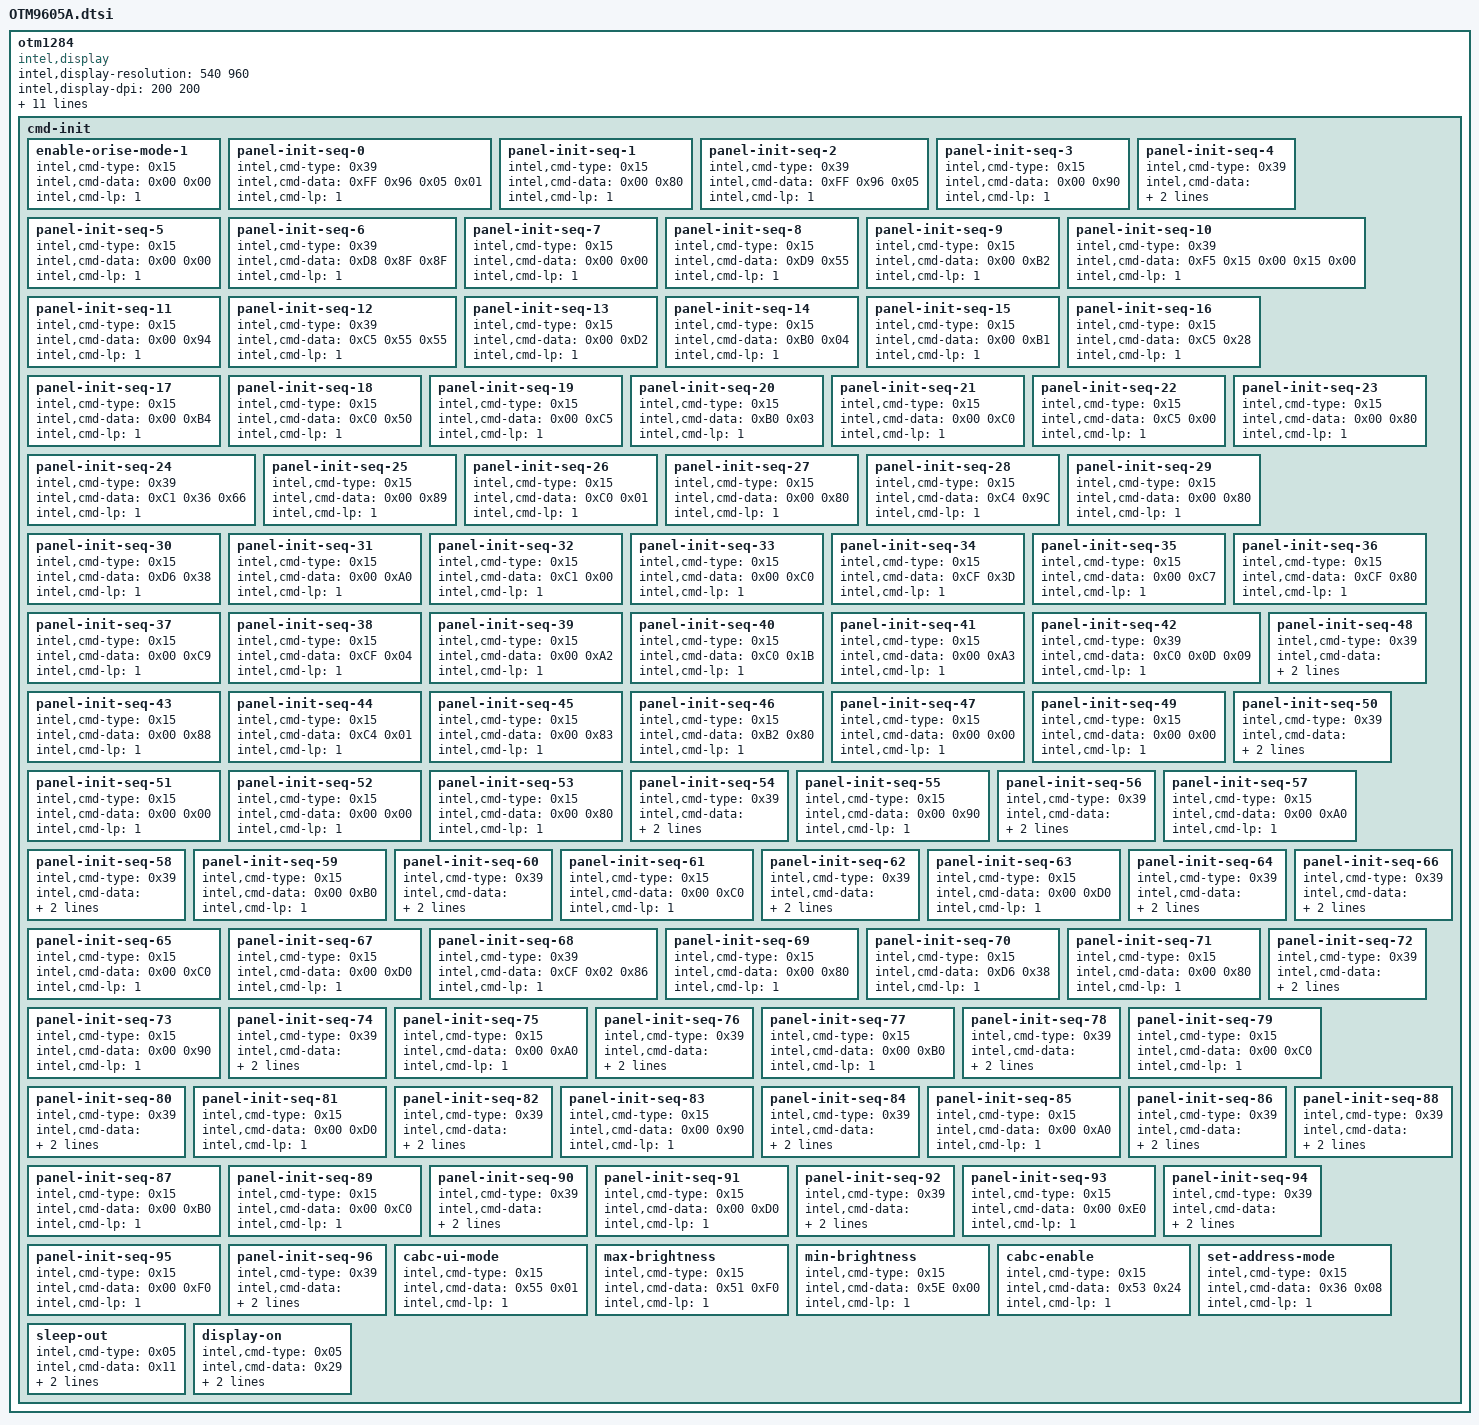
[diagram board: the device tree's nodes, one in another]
	otm1284 {
		compatible = "intel,display";
		intel,display-resolution= <540 960>;
		intel,display-dpi= <200 200>;

		/* MIPI-DSI video mode settings */
		intel,display-vid-hfp-hs-bytes = <93>;
		intel,display-vid-hbp-hs-bytes = <93>;
		intel,display-vid-hsa-hs-bytes = <24>;
		intel,display-vid-vfp-lines = <15>;
		intel,display-vid-vbp-lines = <16>;
		intel,display-vid-vsa-lines = <2>;

		intel,display-vid-mode = "pulses";
		intel,display-vid-id = <0>;
		intel,display-vid-pixel = "24packed";
		intel,display-vid-fill_buf_to = <0x1F>;

		intel,display-reset = <1 1 0 2 1 10>;

		cmd-init {
			enable-orise-mode-1 {
				intel,cmd-type = <0x15>;
				intel,cmd-data = <0x00 0x00>;
				intel,cmd-lp = <1>;
			};
			panel-init-seq-0 {
				intel,cmd-type = <0x39>;
				intel,cmd-data = <0xFF 0x96 0x05 0x01>;
				intel,cmd-lp = <1>;
			};
			panel-init-seq-1 {
				intel,cmd-type = <0x15>;
				intel,cmd-data = <0x00 0x80>;
				intel,cmd-lp = <1>;
			};
			panel-init-seq-2 {
				intel,cmd-type = <0x39>;
				intel,cmd-data = <0xFF 0x96 0x05>;
				intel,cmd-lp = <1>;
			};
			panel-init-seq-3 {
				intel,cmd-type = <0x15>;
				intel,cmd-data = <0x00 0x90>;
				intel,cmd-lp = <1>;
			};
			panel-init-seq-4 {
				intel,cmd-type = <0x39>;
				intel,cmd-data = <0xC5 0x96 0x7B 0x06 0x33 0x55 0x55 0x31>;
				intel,cmd-lp = <1>;
			};
			panel-init-seq-5 {
				intel,cmd-type = <0x15>;
				intel,cmd-data = <0x00 0x00>;
				intel,cmd-lp = <1>;
			};
			panel-init-seq-6 {
				intel,cmd-type = <0x39>;
				intel,cmd-data = <0xD8 0x8F 0x8F>;  //0x8F = 4.9
				intel,cmd-lp = <1>;
			};
	
			panel-init-seq-7 {
				intel,cmd-type = <0x15>;
				intel,cmd-data = <0x00 0x00>;
				intel,cmd-lp = <1>;
			};
			panel-init-seq-8 {
				intel,cmd-type = <0x15>;
				intel,cmd-data = <0xD9 0x55>; //By Panel
				intel,cmd-lp = <1>;
			};
			panel-init-seq-9 {
				intel,cmd-type = <0x15>;
				intel,cmd-data = <0x00 0xB2>;
				intel,cmd-lp = <1>;
			};
			panel-init-seq-10 {
				intel,cmd-type = <0x39>;
				intel,cmd-data = <0xF5 0x15 0x00 0x15 0x00>;
				intel,cmd-lp = <1>;
			};
			panel-init-seq-11 {
				intel,cmd-type = <0x15>;
				intel,cmd-data = <0x00 0x94>;
				intel,cmd-lp = <1>;
			};
			panel-init-seq-12 {
				intel,cmd-type = <0x39>;
				intel,cmd-data = <0xC5 0x55 0x55>;
				intel,cmd-lp = <1>;
			};
			panel-init-seq-13 {
				intel,cmd-type = <0x15>;
				intel,cmd-data = <0x00 0xD2>;
				intel,cmd-lp = <1>;
			};
			panel-init-seq-14 {
				intel,cmd-type = <0x15>;
				intel,cmd-data = <0xB0 0x04>;
				intel,cmd-lp = <1>;
			};
			panel-init-seq-15 {
				intel,cmd-type = <0x15>;
				intel,cmd-data = <0x00 0xB1>;
				intel,cmd-lp = <1>;
			};
			panel-init-seq-16 {
				intel,cmd-type = <0x15>;
				intel,cmd-data = <0xC5 0x28>;
				intel,cmd-lp = <1>;
			};
			panel-init-seq-17 {
				intel,cmd-type = <0x15>;
				intel,cmd-data = <0x00 0xB4>;
				intel,cmd-lp = <1>;
			};
			panel-init-seq-18 {
				intel,cmd-type = <0x15>;
				intel,cmd-data = <0xC0 0x50>;
				intel,cmd-lp = <1>;
			};
			panel-init-seq-19 {
				intel,cmd-type = <0x15>;
				intel,cmd-data = <0x00 0xC5>;
				intel,cmd-lp = <1>;
			};
			panel-init-seq-20 {
				intel,cmd-type = <0x15>;
				intel,cmd-data = <0xB0 0x03>;
				intel,cmd-lp = <1>;
			};
			panel-init-seq-21 {
				intel,cmd-type = <0x15>;
				intel,cmd-data = <0x00 0xC0>;
				intel,cmd-lp = <1>;
			};
			panel-init-seq-22 {
				intel,cmd-type = <0x15>;
				intel,cmd-data = <0xC5 0x00>;
				intel,cmd-lp = <1>;
			};
			panel-init-seq-23 {
				intel,cmd-type = <0x15>;
				intel,cmd-data = <0x00 0x80>;
				intel,cmd-lp = <1>;
			};
			panel-init-seq-24 {
				intel,cmd-type = <0x39>;
				intel,cmd-data = <0xC1 0x36 0x66>;
				intel,cmd-lp = <1>;
			};
			panel-init-seq-25 {
				intel,cmd-type = <0x15>;
				intel,cmd-data = <0x00 0x89>;
				intel,cmd-lp = <1>;
			};
			panel-init-seq-26 {
				intel,cmd-type = <0x15>;
				intel,cmd-data = <0xC0 0x01>;
				intel,cmd-lp = <1>;
			};
			panel-init-seq-27 {
				intel,cmd-type = <0x15>;
				intel,cmd-data = <0x00 0x80>;
				intel,cmd-lp = <1>;
			};
			panel-init-seq-28 {
				intel,cmd-type = <0x15>;
				intel,cmd-data = <0xC4 0x9C>;
				intel,cmd-lp = <1>;
			};
			panel-init-seq-29 {
				intel,cmd-type = <0x15>;
				intel,cmd-data = <0x00 0x80>;
				intel,cmd-lp = <1>;
			};
			panel-init-seq-30 {
				intel,cmd-type = <0x15>;
				intel,cmd-data = <0xD6 0x38>;
				intel,cmd-lp = <1>;
			};
			panel-init-seq-31 {
				intel,cmd-type = <0x15>;
				intel,cmd-data = <0x00 0xA0>;
				intel,cmd-lp = <1>;
			};
			panel-init-seq-32 {
				intel,cmd-type = <0x15>;
				intel,cmd-data = <0xC1 0x00>;
				intel,cmd-lp = <1>;
			};
			panel-init-seq-33 {
				intel,cmd-type = <0x15>;
				intel,cmd-data = <0x00 0xC0>;
				intel,cmd-lp = <1>;
			};
			panel-init-seq-34 {
				intel,cmd-type = <0x15>;
				intel,cmd-data = <0xCF 0x3D>;
				intel,cmd-lp = <1>;
			};
			panel-init-seq-35 {
				intel,cmd-type = <0x15>;
				intel,cmd-data = <0x00 0xC7>;
				intel,cmd-lp = <1>;
			};
			panel-init-seq-36 {
				intel,cmd-type = <0x15>;
				intel,cmd-data = <0xCF 0x80>;
				intel,cmd-lp = <1>;
			};
			panel-init-seq-37 {
				intel,cmd-type = <0x15>;
				intel,cmd-data = <0x00 0xC9>;
				intel,cmd-lp = <1>;
			};
			panel-init-seq-38 {
				intel,cmd-type = <0x15>;
				intel,cmd-data = <0xCF 0x04>;
				intel,cmd-lp = <1>;
			};
			panel-init-seq-39 {
				intel,cmd-type = <0x15>;
				intel,cmd-data = <0x00 0xA2>; //0xC0A2 PL
				intel,cmd-lp = <1>;
			};
			panel-init-seq-40 {
				intel,cmd-type = <0x15>;
				intel,cmd-data = <0xC0 0x1B>;
				intel,cmd-lp = <1>;
			};
			panel-init-seq-41 {
				intel,cmd-type = <0x15>;
				intel,cmd-data = <0x00 0xA3>; //0xC0A2-A3 PCH1+PCH2
				intel,cmd-lp = <1>;
			};
			panel-init-seq-42 {
				intel,cmd-type = <0x39>;
				intel,cmd-data = <0xC0 0x0D 0x09>;
				intel,cmd-lp = <1>;
			};
			panel-init-seq-43 {
				intel,cmd-type = <0x15>;
				intel,cmd-data = <0x00 0x88>; //0xC488 CR
				intel,cmd-lp = <1>;
			};
			panel-init-seq-44 {
				intel,cmd-type = <0x15>;
				intel,cmd-data = <0xC4 0x01>;
				intel,cmd-lp = <1>;
			};
			panel-init-seq-45 {
				intel,cmd-type = <0x15>;
				intel,cmd-data = <0x00 0x83>;
				intel,cmd-lp = <1>;
			};
			panel-init-seq-46 {
				intel,cmd-type = <0x15>;
				intel,cmd-data = <0xB2 0x80>;
				intel,cmd-lp = <1>;
			};
			panel-init-seq-47 {
				intel,cmd-type = <0x15>;
				intel,cmd-data = <0x00 0x00>;
				intel,cmd-lp = <1>;
			};
			panel-init-seq-48 {
				intel,cmd-type = <0x39>;
				intel,cmd-data = <0xE1 0x03 0x07 0x0D 0x0D 0x06 0x0E 0x0D 0x08 0x04 0x08 0x0B 0x08 0x0E 0x16 0x11 0x0A>;
				intel,cmd-lp = <1>;
			};
			panel-init-seq-49 {
				intel,cmd-type = <0x15>;
				intel,cmd-data = <0x00 0x00>;
				intel,cmd-lp = <1>;
			};
			panel-init-seq-50 {
				intel,cmd-type = <0x39>;
				intel,cmd-data = <0xE2 0x03 0x07 0x0D 0x0D 0x06 0x0E 0x0D 0x08 0x04 0x08 0x0B 0x08 0x0E 0x16 0x11 0x0A>;
				intel,cmd-lp = <1>;
			};
			panel-init-seq-51 {
				intel,cmd-type = <0x15>;
				intel,cmd-data = <0x00 0x00>;
				intel,cmd-lp = <1>;
			};
			panel-init-seq-52 {
				intel,cmd-type = <0x15>;
				intel,cmd-data = <0x00 0x00>;
				intel,cmd-lp = <1>;
			};
			panel-init-seq-53 {
				intel,cmd-type = <0x15>;
				intel,cmd-data = <0x00 0x80>;
				intel,cmd-lp = <1>;
			};
			panel-init-seq-54 {
				intel,cmd-type = <0x39>;
				intel,cmd-data = <0xCE 0x8B 0x03 0x00 0x8A 0x03 0x00 0x00 0x00 0x00 0x00 0x00 0x00>;
				intel,cmd-lp = <1>;
			};
			panel-init-seq-55 {
				intel,cmd-type = <0x15>;
				intel,cmd-data = <0x00 0x90>;
				intel,cmd-lp = <1>;
			};
			panel-init-seq-56 {
				intel,cmd-type = <0x39>;
				intel,cmd-data = <0xCE 0x00 0x00 0x00 0x00 0x00 0x00 0x00 0x00 0x00 0x00 0x00 0x00 0x00 0x00>;
				intel,cmd-lp = <1>;
			};
			panel-init-seq-57 {
				intel,cmd-type = <0x15>;
				intel,cmd-data = <0x00 0xA0>;
				intel,cmd-lp = <1>;
			};
			panel-init-seq-58 {
				intel,cmd-type = <0x39>;
				intel,cmd-data = <0xCE 0x38 0x09 0x03 0xC2 0x00 0x17 0x00 0x38 0x08 0x03 0xC3 0x00 0x17 0x00>;
				intel,cmd-lp = <1>;
			};
			panel-init-seq-59 {
				intel,cmd-type = <0x15>;
				intel,cmd-data = <0x00 0xB0>;
				intel,cmd-lp = <1>;
			};
			panel-init-seq-60 {
				intel,cmd-type = <0x39>;
				intel,cmd-data = <0xCE 0x38 0x07 0x03 0xC4 0x00 0x17 0x00 0x38 0x06 0x03 0xCA 0x00 0x17 0x00>;
				intel,cmd-lp = <1>;
			};
			panel-init-seq-61 {
				intel,cmd-type = <0x15>;
				intel,cmd-data = <0x00 0xC0>;
				intel,cmd-lp = <1>;
			};
			panel-init-seq-62 {
				intel,cmd-type = <0x39>;
				intel,cmd-data = <0xCE 0x38 0x05 0x03 0xC6 0x00 0x17 0x00 0x38 0x04 0x03 0xC7 0x00 0x17 0x00>;
				intel,cmd-lp = <1>;
			};
			panel-init-seq-63 {
				intel,cmd-type = <0x15>;
				intel,cmd-data = <0x00 0xD0>;
				intel,cmd-lp = <1>;
			};
			panel-init-seq-64 {
				intel,cmd-type = <0x39>;
				intel,cmd-data = <0xCE 0x38 0x03 0x03 0xC8 0x00 0x17 0x00 0x38 0x02 0x03 0xC9 0x00 0x17 0x00>;
				intel,cmd-lp = <1>;
			};
			panel-init-seq-65 {
				intel,cmd-type = <0x15>;
				intel,cmd-data = <0x00 0xC0>;
				intel,cmd-lp = <1>;
			};
			panel-init-seq-66 {
				intel,cmd-type = <0x39>;
				intel,cmd-data = <0xCF 0x09 0x02 0x20 0x20 0x00 0x00 0x01 0x80 0x20 0x04>;
				intel,cmd-lp = <1>;
			};
			panel-init-seq-67 {
				intel,cmd-type = <0x15>;
				intel,cmd-data = <0x00 0xD0>;
				intel,cmd-lp = <1>;
			};
			panel-init-seq-68 {
				intel,cmd-type = <0x39>;
				intel,cmd-data = <0xCF 0x02 0x86>;
				intel,cmd-lp = <1>;
			};
			panel-init-seq-69 {
				intel,cmd-type = <0x15>;
				intel,cmd-data = <0x00 0x80>;
				intel,cmd-lp = <1>;
			};
			panel-init-seq-70 {
				intel,cmd-type = <0x15>;
				intel,cmd-data = <0xD6 0x38>;
				intel,cmd-lp = <1>;
			};
			panel-init-seq-71 {
				intel,cmd-type = <0x15>;
				intel,cmd-data = <0x00 0x80>;
				intel,cmd-lp = <1>;
			};
			panel-init-seq-72 {
				intel,cmd-type = <0x39>;
				intel,cmd-data = <0xCC 0x00 0x00 0x00 0x02 0x00 0x0A 0x0C 0x0E 0x10 0x00>;
				intel,cmd-lp = <1>;
			};
			panel-init-seq-73 {
				intel,cmd-type = <0x15>;
				intel,cmd-data = <0x00 0x90>;
				intel,cmd-lp = <1>;
			};
			panel-init-seq-74 {
				intel,cmd-type = <0x39>;
				intel,cmd-data = <0xCC 0x21 0x00 0x22 0x00 0x00 0x00 0x00 0x00 0x00 0x00 0x00 0x00 0x00 0x01 0x00>;
				intel,cmd-lp = <1>;
			};
			panel-init-seq-75 {
				intel,cmd-type = <0x15>;
				intel,cmd-data = <0x00 0xA0>;
				intel,cmd-lp = <1>;
			};
			panel-init-seq-76 {
				intel,cmd-type = <0x39>;
				intel,cmd-data = <0xCC 0x09 0x0B 0x0D 0x0F 0x00 0x21 0x00 0x22 0x00 0x00 0x00 0x00 0x00 0x00 0x00>;
				intel,cmd-lp = <1>;
			};
			panel-init-seq-77 {
				intel,cmd-type = <0x15>;
				intel,cmd-data = <0x00 0xB0>;
				intel,cmd-lp = <1>;
			};
			panel-init-seq-78 {
				intel,cmd-type = <0x39>;
				intel,cmd-data = <0xCC 0x00 0x00 0x00 0x00 0x00 0x00 0x00 0x00 0x00 0x00>;
				intel,cmd-lp = <1>;
			};
			panel-init-seq-79 {
				intel,cmd-type = <0x15>;
				intel,cmd-data = <0x00 0xC0>;
				intel,cmd-lp = <1>;
			};
			panel-init-seq-80 {
				intel,cmd-type = <0x39>;
				intel,cmd-data = <0xCC 0x00 0x00 0x00 0x00 0x00 0x00 0x00 0x00 0x00 0x00 0x00 0x00 0x00 0x00 0x00>;
				intel,cmd-lp = <1>;
			};
			panel-init-seq-81 {
				intel,cmd-type = <0x15>;
				intel,cmd-data = <0x00 0xD0>;
				intel,cmd-lp = <1>;
			};
			panel-init-seq-82 {
				intel,cmd-type = <0x39>;
				intel,cmd-data = <0xCC 0x00 0x00 0x00 0x00 0x00 0x00 0x00 0x00 0x00 0x00 0x00 0x00 0x00 0x00 0x00>;
				intel,cmd-lp = <1>;
			};
			panel-init-seq-83 {
				intel,cmd-type = <0x15>;
				intel,cmd-data = <0x00 0x90>;
				intel,cmd-lp = <1>;
			};
			panel-init-seq-84 {
				intel,cmd-type = <0x39>;
				intel,cmd-data = <0xCB 0x00 0x00 0x00 0x04 0x04 0x04 0x04 0x04 0x04 0x00 0x04 0x00 0x04 0x00 0x00>;
				intel,cmd-lp = <1>;
			};
			panel-init-seq-85 {
				intel,cmd-type = <0x15>;
				intel,cmd-data = <0x00 0xA0>;
				intel,cmd-lp = <1>;
			};
			panel-init-seq-86 {
				intel,cmd-type = <0x39>;
				intel,cmd-data = <0xCB 0x00 0x00 0x00 0x00 0x00 0x00 0x00 0x00 0x04 0x04 0x04 0x04 0x04 0x04 0x00>;
				intel,cmd-lp = <1>;
			};
			panel-init-seq-87 {
				intel,cmd-type = <0x15>;
				intel,cmd-data = <0x00 0xB0>;
				intel,cmd-lp = <1>;
			};
			panel-init-seq-88 {
				intel,cmd-type = <0x39>;
				intel,cmd-data = <0xCB 0x04 0x00 0x04 0x00 0x00 0x00 0x00 0x00 0x00 0x00>;
				intel,cmd-lp = <1>;
			};
			panel-init-seq-89 {
				intel,cmd-type = <0x15>;
				intel,cmd-data = <0x00 0xC0>;
				intel,cmd-lp = <1>;
			};
			panel-init-seq-90 {
				intel,cmd-type = <0x39>;
				intel,cmd-data = <0xCB 0x00 0x00 0x00 0x04 0x04 0x04 0x04 0x04 0x04 0x00 0x04 0x00 0x04 0x00 0x00>;
				intel,cmd-lp = <1>;
			};
			panel-init-seq-91 {
				intel,cmd-type = <0x15>;
				intel,cmd-data = <0x00 0xD0>;
				intel,cmd-lp = <1>;
			};
			panel-init-seq-92 {
				intel,cmd-type = <0x39>;
				intel,cmd-data = <0xCB 0x00 0x00 0x00 0x00 0x00 0x00 0x00 0x00 0x04 0x04 0x04 0x04 0x04 0x04 0x00>;
				intel,cmd-lp = <1>;
			};
			panel-init-seq-93 {
				intel,cmd-type = <0x15>;
				intel,cmd-data = <0x00 0xE0>;
				intel,cmd-lp = <1>;
			};
			panel-init-seq-94 {
				intel,cmd-type = <0x39>;
				intel,cmd-data = <0xCB 0x04 0x00 0x04 0x00 0x00 0x00 0x00 0x00 0x00 0x00>;
				intel,cmd-lp = <1>;
			};
			panel-init-seq-95 {
				intel,cmd-type = <0x15>;
				intel,cmd-data = <0x00 0xF0>;
				intel,cmd-lp = <1>;
			};
			panel-init-seq-96 {
				intel,cmd-type = <0x39>;
				intel,cmd-data = <0xCB 0xFF 0xFF 0xFF 0xFF 0xFF 0xFF 0xFF 0xFF 0xFF 0xFF>;
				intel,cmd-lp = <1>;
			};

			cabc-ui-mode{
				intel,cmd-type = <0x15>;
				intel,cmd-data = <0x55 0x01>;
				intel,cmd-lp = <1>;
			};
			max-brightness{
				intel,cmd-type = <0x15>;
				intel,cmd-data = <0x51 0xF0>;
				intel,cmd-lp = <1>;
			};
			min-brightness{
				intel,cmd-type = <0x15>;
				intel,cmd-data = <0x5E 0x00>;
				intel,cmd-lp = <1>;
			};
			cabc-enable{
				intel,cmd-type = <0x15>;
				intel,cmd-data = <0x53 0x24>;
				intel,cmd-lp = <1>;
			};
			set-address-mode {
				intel,cmd-type = <0x15>;
				intel,cmd-data = <0x36 0x08>;
				intel,cmd-lp = <1>;
			};
			sleep-out{
				intel,cmd-type = <0x05>;
				intel,cmd-data = <0x11>;
				intel,cmd-delay = <120>;
				intel,cmd-lp = <1>;
			};
			display-on{
				intel,cmd-type = <0x05>;
				intel,cmd-data = <0x29>;
				intel,cmd-delay = <5>;
				intel,cmd-lp = <1>;
			};
		};
/*
		cmd-sleep-out {
			sleep-out{
				intel,cmd-type = <0x05>;
				intel,cmd-data = <0x11>;
				intel,cmd-delay = <5>;
				intel,cmd-lp = <1>;
			};
			display-on{
				intel,cmd-type = <0x05>;
				intel,cmd-data = <0x29>;
				intel,cmd-delay = <5>;
				intel,cmd-lp = <1>;
			};
		};
		cmd-update {
			send-data {
				intel,cmd-type = <0x39>;
				intel,cmd-data = <0x2C>;
			};
		};
	*/
	};
